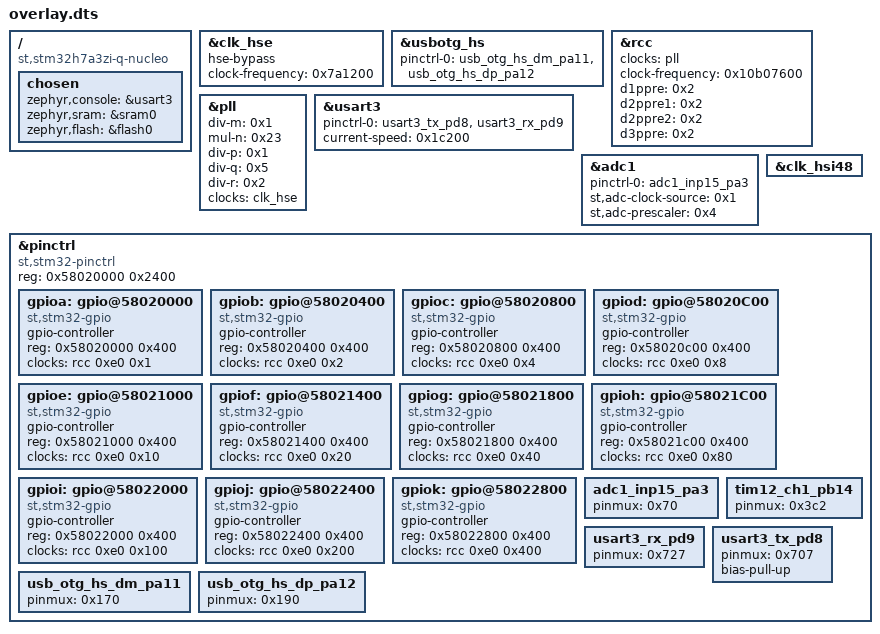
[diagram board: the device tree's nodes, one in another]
/ {
	compatible = "st,stm32h7a3zi-q-nucleo";
	chosen {
		zephyr,console = &usart3;
		zephyr,sram = &sram0;
		zephyr,flash = &flash0;
	};
};
&clk_hse{
	status = "okay";
	hse-bypass;
	clock-frequency = < 0x7a1200 >;
};
&usbotg_hs{
	status = "okay";
	pinctrl-0 = < &usb_otg_hs_dm_pa11 &usb_otg_hs_dp_pa12 >;
	pinctrl-names = "default";
};
&rcc{
	clocks = < &pll >;
	clock-frequency = < 0x10b07600 >;
	d1ppre = < 0x2 >;
	d2ppre1 = < 0x2 >;
	d2ppre2 = < 0x2 >;
	d3ppre = < 0x2 >;
};
&pll{
	status = "okay";
	div-m = < 0x1 >;
	mul-n = < 0x23 >;
	div-p = < 0x1 >;
	div-q = < 0x5 >;
	div-r = < 0x2 >;
	clocks = < &clk_hse >;
};
&usart3{
	status = "okay";
	pinctrl-0 = < &usart3_tx_pd8 &usart3_rx_pd9 >;
	pinctrl-names = "default";
	current-speed = < 0x1c200 >;
};
&adc1{
	status = "okay";
	pinctrl-0 = < &adc1_inp15_pa3 >;
	pinctrl-names = "default";
	st,adc-clock-source = < 0x1 >;
	st,adc-prescaler = < 0x4 >;
};
&clk_hsi48{
	status = "okay";
};
&pinctrl{
	compatible = "st,stm32-pinctrl";
	#address-cells = < 0x1 >;
	#size-cells = < 0x1 >;
	reg = < 0x58020000 0x2400 >;
	gpioa: gpio@58020000 {
		compatible = "st,stm32-gpio";
		gpio-controller;
		#gpio-cells = < 0x2 >;
		reg = < 0x58020000 0x400 >;
		clocks = < &rcc 0xe0 0x1 >;
	};
	gpiob: gpio@58020400 {
		compatible = "st,stm32-gpio";
		gpio-controller;
		#gpio-cells = < 0x2 >;
		reg = < 0x58020400 0x400 >;
		clocks = < &rcc 0xe0 0x2 >;
	};
	gpioc: gpio@58020800 {
		compatible = "st,stm32-gpio";
		gpio-controller;
		#gpio-cells = < 0x2 >;
		reg = < 0x58020800 0x400 >;
		clocks = < &rcc 0xe0 0x4 >;
	};
	gpiod: gpio@58020C00 {
		compatible = "st,stm32-gpio";
		gpio-controller;
		#gpio-cells = < 0x2 >;
		reg = < 0x58020c00 0x400 >;
		clocks = < &rcc 0xe0 0x8 >;
	};
	gpioe: gpio@58021000 {
		compatible = "st,stm32-gpio";
		gpio-controller;
		#gpio-cells = < 0x2 >;
		reg = < 0x58021000 0x400 >;
		clocks = < &rcc 0xe0 0x10 >;
	};
	gpiof: gpio@58021400 {
		compatible = "st,stm32-gpio";
		gpio-controller;
		#gpio-cells = < 0x2 >;
		reg = < 0x58021400 0x400 >;
		clocks = < &rcc 0xe0 0x20 >;
	};
	gpiog: gpio@58021800 {
		compatible = "st,stm32-gpio";
		gpio-controller;
		#gpio-cells = < 0x2 >;
		reg = < 0x58021800 0x400 >;
		clocks = < &rcc 0xe0 0x40 >;
	};
	gpioh: gpio@58021C00 {
		compatible = "st,stm32-gpio";
		gpio-controller;
		#gpio-cells = < 0x2 >;
		reg = < 0x58021c00 0x400 >;
		clocks = < &rcc 0xe0 0x80 >;
	};
	gpioi: gpio@58022000 {
		compatible = "st,stm32-gpio";
		gpio-controller;
		#gpio-cells = < 0x2 >;
		reg = < 0x58022000 0x400 >;
		clocks = < &rcc 0xe0 0x100 >;
	};
	gpioj: gpio@58022400 {
		compatible = "st,stm32-gpio";
		gpio-controller;
		#gpio-cells = < 0x2 >;
		reg = < 0x58022400 0x400 >;
		clocks = < &rcc 0xe0 0x200 >;
	};
	gpiok: gpio@58022800 {
		compatible = "st,stm32-gpio";
		gpio-controller;
		#gpio-cells = < 0x2 >;
		reg = < 0x58022800 0x400 >;
		clocks = < &rcc 0xe0 0x400 >;
	};
	adc1_inp15_pa3: adc1_inp15_pa3 {
		pinmux = < 0x70 >;
	};
	tim12_ch1_pb14: tim12_ch1_pb14 {
		pinmux = < 0x3c2 >;
	};
	usart3_rx_pd9: usart3_rx_pd9 {
		pinmux = < 0x727 >;
	};
	usart3_tx_pd8: usart3_tx_pd8 {
		pinmux = < 0x707 >;
		bias-pull-up;
	};
	usb_otg_hs_dm_pa11: usb_otg_hs_dm_pa11 {
		pinmux = < 0x170 >;
	};
	usb_otg_hs_dp_pa12: usb_otg_hs_dp_pa12 {
		pinmux = < 0x190 >;
	};
};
